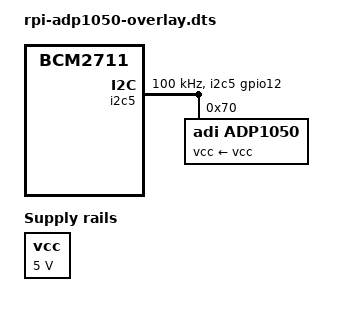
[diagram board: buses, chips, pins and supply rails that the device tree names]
// SPDX-License-Identifier: (GPL-2.0+)
/* Overlay for SENSORS_ADP1050
 *
 * Copyright 2024 Analog Devices Inc.
 */

/dts-v1/;
/plugin/;

/ {
	compatible = "brcm, bcm2711";

	vcc: regulator {
		compatible = "regulator-fixed";
		regulator-name = "vcc";
		regulator-min-microvolt = <5000000>;
		regulator-max-microvolt = <5000000>;
		regulator-boot-on;
		regulator-always-on;
	};
};

&i2c5 {
	status = "okay";
	clock-frequency = <100000>;
	pinctrl-names = "default";
	pinctrl-0 = <&i2c5_gpio12>;

	adp1050@70 {
		compatible = "adi,adp1050";
		reg = <0x70>;
		vcc-supply = <&vcc>;
	};
};
